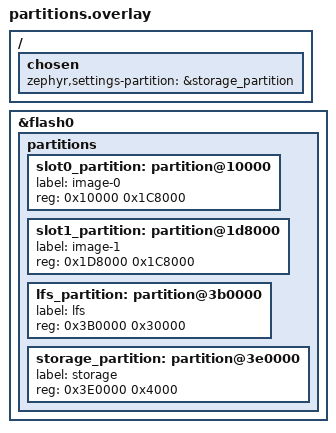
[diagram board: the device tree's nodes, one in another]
/*
 * Shared app/MCUboot flash map. slot0 at 0x10000 (Arduino app offset),
 * lfs @0x3B0000, storage @0x3E0000.
 */
/delete-node/ &sys_partition;
/delete-node/ &slot0_partition;
/delete-node/ &slot1_partition;
/delete-node/ &storage_partition;
/delete-node/ &scratch_partition;

/ {
	chosen {
		zephyr,settings-partition = &storage_partition;
	};
};

&flash0 {
	partitions {
		slot0_partition: partition@10000 {
			label = "image-0";
			reg = <0x10000 0x1C8000>;
		};
		slot1_partition: partition@1d8000 {
			label = "image-1";
			reg = <0x1D8000 0x1C8000>;
		};
		lfs_partition: partition@3b0000 {
			label = "lfs";
			reg = <0x3B0000 0x30000>;
		};
		storage_partition: partition@3e0000 {
			label = "storage";
			reg = <0x3E0000 0x4000>;
		};
	};
};
